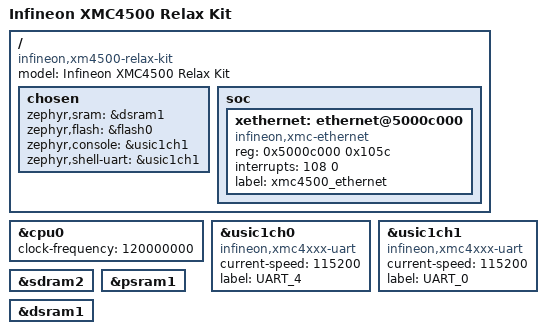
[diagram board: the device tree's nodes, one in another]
/*
 * SPDX-License-Identifier: Apache-2.0
 *
 * Copyright (c) 2020 Linumiz
 * Author: Parthiban Nallathambi <parthiban@linumiz.com>
 *
 */

/dts-v1/;

#include <infineon/xmc4500.dtsi>

/ {
	model = "Infineon XMC4500 Relax Kit";
	compatible = "infineon,xm4500-relax-kit", "infineon,xmc4500",
						"infineon,xmc4xxx";

	chosen {
		zephyr,sram = &dsram1;
		zephyr,flash = &flash0;
		zephyr,console = &usic1ch1;
		zephyr,shell-uart = &usic1ch1;
	};

	soc {

		xethernet: ethernet@5000c000 {
			compatible = "infineon,xmc-ethernet";
			reg = <0x5000c000 0x105c>;
			interrupts = <108 0>;
			status = "okay";
			label = "xmc4500_ethernet";
		};

	};
};

&cpu0 {
	clock-frequency = <120000000>;
};

&usic1ch0 {
	compatible = "infineon,xmc4xxx-uart";
	current-speed = <115200>;
	label = "UART_4";
	status = "okay";
};

&usic1ch1 {
	compatible = "infineon,xmc4xxx-uart";
	current-speed = <115200>;
	label = "UART_0";
	status = "okay";
};

&sdram2 {
	status = "okay";
};

&psram1 {
	status = "okay";
};

&dsram1 {
	status = "okay";
};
